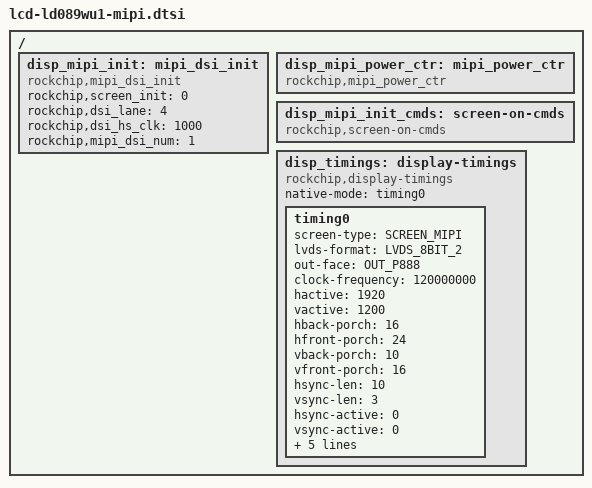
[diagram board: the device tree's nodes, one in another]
/*
 * Copyright (C) 2014 ROCKCHIP, Inc.
 * arch/arm/boot/dts/lcd-lq070m1sx01-mipi.dtsi
 * author: libing@rock-chips.com
 * create date: 2014-04-15
 * lcd model: ld089wu1 
 * resolution: 1920 X 1200
 * mipi channel: single
 */

/ {
		/* about mipi */
		disp_mipi_init: mipi_dsi_init{
					compatible = "rockchip,mipi_dsi_init";
					rockchip,screen_init	= <0>;
					rockchip,dsi_lane		= <4>;
					rockchip,dsi_hs_clk		= <1000>;
					rockchip,mipi_dsi_num	= <1>;
		};
		disp_mipi_power_ctr: mipi_power_ctr {
					compatible = "rockchip,mipi_power_ctr";
					/*mipi_lcd_rst:mipi_lcd_rst{
							compatible = "rockchip,lcd_rst";
							rockchip,gpios = <&gpio2 GPIO_B7 GPIO_ACTIVE_LOW>;
							rockchip,delay = <100>;
					};
					mipi_lcd_en:mipi_lcd_en {
							compatible = "rockchip,lcd_en";
							rockchip,gpios = <&gpio0 GPIO_C1 GPIO_ACTIVE_HIGH>;
							rockchip,delay = <100>;
					};*/
		};
		disp_mipi_init_cmds: screen-on-cmds {
					compatible = "rockchip,screen-on-cmds";
					/*rockchip,cmd_debug = <1>;
					rockchip,on-cmds1 {
							compatible = "rockchip,on-cmds";
							rockchip,cmd_type = <HSDT>;
							rockchip,dsi_id = <2>;
							rockchip,cmd = <0xb0 0x02>;
							rockchip,cmd_delay = <0>;
					};
					*/
		};


		disp_timings: display-timings {
                        native-mode = <&timing0>;
                        compatible = "rockchip,display-timings";
                        timing0: timing0 {
				screen-type = <SCREEN_MIPI>;
				lvds-format = <LVDS_8BIT_2>;
				out-face    = <OUT_P888>;
				clock-frequency = <120000000>;
				hactive = <1920>;
				vactive = <1200>;
				hback-porch = <16>;
				hfront-porch = <24>;
				vback-porch = <10>;
				vfront-porch = <16>;
				hsync-len = <10>;
				vsync-len = <3>;
				hsync-active = <0>;
				vsync-active = <0>;
				de-active = <0>;
				pixelclk-active = <0>;
				swap-rb = <0>;
				swap-rg = <0>;
				swap-gb = <0>;
                     	};
               };
};
